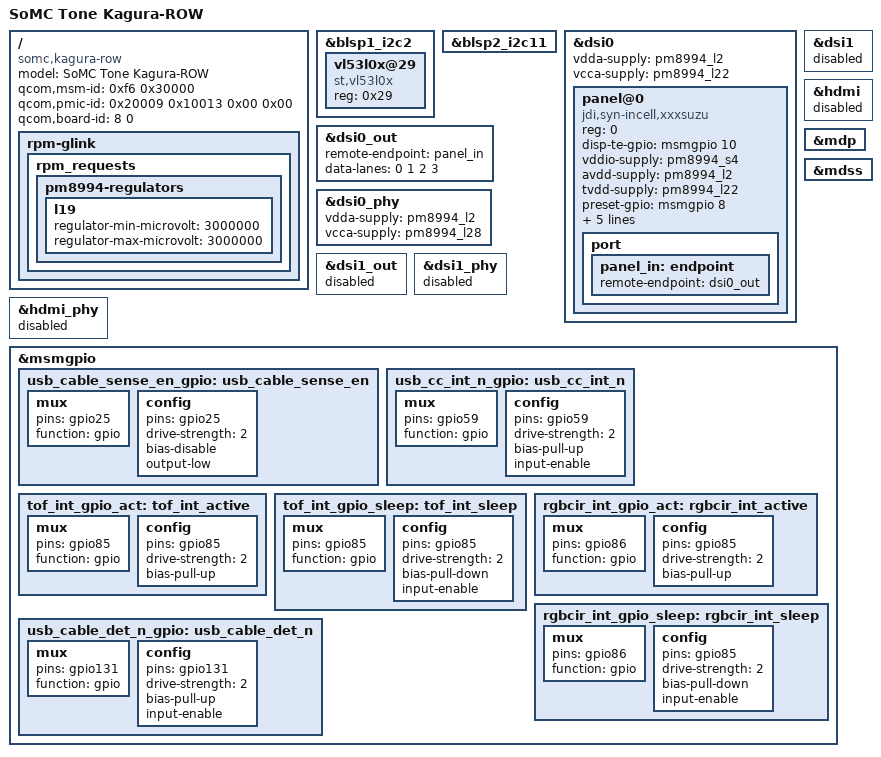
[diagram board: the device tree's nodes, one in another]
// SPDX-License-Identifier: GPL-2.0
/* Copyright (C) 2016 Sony Mobile Communications Inc.
 * Copyright (c) 2019 AngeloGioacchino Del Regno <kholk11@gmail.com>
 */

/dts-v1/;

#include "msm8996-sony-xperia-tone.dtsi"
//#include "msm8996.dtsi"

/ {
	model = "SoMC Tone Kagura-ROW";
	compatible = "somc,kagura-row", "qcom,msm8996";
	qcom,msm-id = <0xf6 0x30000>;
	qcom,pmic-id = <0x20009 0x10013 0x00 0x00>;
	qcom,board-id = <8 0>;

	rpm-glink {
		rpm_requests {
			pm8994-regulators {
				l19 {
					regulator-min-microvolt = <3000000>;
					regulator-max-microvolt = <3000000>;
				};
			};
		};
	};
};

&blsp1_i2c2 {
	vl53l0x@29 {
		compatible = "st,vl53l0x";
		reg = <0x29>;
	};
};

&blsp2_i2c11 {
#if 0
	fusb301@25 {
		status = "okay";
		compatible = "fusb301";
		reg = <0x25>;
		interrupt-parent = <&msmgpio>;
		interrupts = <0x3b 0x02>, <0x83 0x03>;
		fusb301,cbl_sns-enabled;
		fusb301,cbl_sns-gpio = <&msmgpio 0x19 0x00>;
		fusb301,int-gpio = <&msmgpio 0x3b 0x00>;
		fusb301,cbl_det-gpio = <&msmgpio 0x83 0x00>;
		fusb301,use-try-snk-emulation;
		fusb301,ext_typec_ctrl-enabled;
		pinctrl-names = "default";
		pinctrl-0 = <&usb_cable_det_n_gpio &usb_cable_sense_en_gpio
				&usb_cc_int_n_gpio>;
	};
#endif
};

&dsi0 {
	status = "okay";

	vdda-supply = <&pm8994_l2>;
	vcca-supply = <&pm8994_l22>;
	
	/* 
	 * The panel ONLY seems to initialize properly if you flash the kernel
	 * and coldboot the device so that bootloader can set some things up.
	 * Hence, "fastboot boot" ain't gonna cut it, chief.
	 */
	panel@0 {
		compatible = "jdi,syn-incell,xxxsuzu";
		reg = <0>;
		status = "okay";
		disp-te-gpio = <&msmgpio 10 0>;

		vddio-supply = <&pm8994_s4>;
		avdd-supply = <&pm8994_l2>;
		tvdd-supply = <&pm8994_l22>;

		//pvddio-gpio = <&msmgpio 51 GPIO_ACTIVE_HIGH>;
		preset-gpio = <&msmgpio 8 GPIO_ACTIVE_HIGH>;
		tvddio-gpio = <&msmgpio 50 GPIO_ACTIVE_HIGH>;
		treset-gpio = <&msmgpio 89 GPIO_ACTIVE_HIGH>;

		pinctrl-names = "default";
		pinctrl-0 =
			<&mdp_vsync_p_gpio &disp_reset_n_gpio
			&tp_vddio_en_gpio &lcd_vddio_en_gpio
			&ts_reset_n_gpio>;

		port {
			panel_in: endpoint {
				remote-endpoint = <&dsi0_out>;
			};
		};
	};
};

&dsi0_out {
	remote-endpoint = <&panel_in>;
	data-lanes = <0 1 2 3>;
};

&dsi0_phy {
	status = "okay";

	vdda-supply = <&pm8994_l2>;
	vcca-supply = <&pm8994_l28>;
};

&dsi1 {
	status = "disabled";
};

&dsi1_out {
	status = "disabled";
};

&dsi1_phy {
	status = "disabled";
};

&hdmi {
	status = "disabled";
};

&hdmi_phy {
	status = "disabled";
};

&mdp {
	status = "okay";
};

&mdss {
	status = "okay";
};

/* Pins */
&msmgpio {
	usb_cable_sense_en_gpio: usb_cable_sense_en {
		mux {
			pins = "gpio25";
			function = "gpio";
		};

		config {
			pins = "gpio25";
			drive-strength = <2>;
			bias-disable;
			output-low;
		};
	};

	usb_cc_int_n_gpio: usb_cc_int_n {
		mux {
			pins = "gpio59";
			function = "gpio";
		};

		config {
			pins = "gpio59";
			drive-strength = <2>;
			bias-pull-up;
			input-enable;
		};
	};

	tof_int_gpio_act: tof_int_active {
		mux {
			pins = "gpio85";
			function = "gpio";
		};

		config {
			pins = "gpio85";
			drive-strength = <2>;
			bias-pull-up;
		};
	};

	tof_int_gpio_sleep: tof_int_sleep {
		mux {
			pins = "gpio85";
			function = "gpio";
		};

		config {
			pins = "gpio85";
			drive-strength = <2>;
			bias-pull-down;
			input-enable;
		};
	};

	rgbcir_int_gpio_act: rgbcir_int_active {
		mux {
			pins = "gpio86";
			function = "gpio";
		};

		config {
			pins = "gpio85";
			drive-strength = <2>;
			bias-pull-up;
		};
	};

	rgbcir_int_gpio_sleep: rgbcir_int_sleep {
		mux {
			pins = "gpio86";
			function = "gpio";
		};

		config {
			pins = "gpio85";
			drive-strength = <2>;
			bias-pull-down;
			input-enable;
		};
	};

	usb_cable_det_n_gpio: usb_cable_det_n {
		mux {
			pins = "gpio131";
			function = "gpio";
		};

		config {
			pins = "gpio131";
			drive-strength = <2>;
			bias-pull-up;
			input-enable;
		};
	};
};
